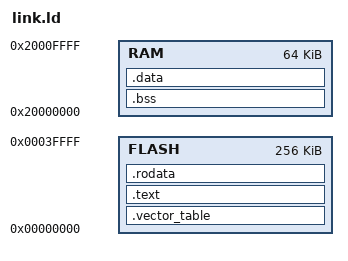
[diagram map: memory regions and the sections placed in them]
/* Memory layout of the LM3S6965 microcontroller */
/* 1K = 1 KiBi = 1024 bytes */
MEMORY
{
  FLASH : ORIGIN = 0x00000000, LENGTH = 256K
  RAM : ORIGIN = 0x20000000, LENGTH = 64K
}

/* The entry point is the reset handler */
ENTRY(Reset);

EXTERN(RESET_VECTOR);
EXTERN(EXCEPTIONS);

/* PROVIDE: 只有左边在所有输入的o中都没找到，才会生效！这样避免使用weak*/
PROVIDE(NMI = DefaultExceptionHandler);
PROVIDE(HardFault = DefaultExceptionHandler);
PROVIDE(MemManage = DefaultExceptionHandler);
PROVIDE(BusFault = DefaultExceptionHandler);
PROVIDE(UsageFault = DefaultExceptionHandler);
PROVIDE(SVCall = DefaultExceptionHandler);
PROVIDE(PendSV = DefaultExceptionHandler);
PROVIDE(SysTick = DefaultExceptionHandler);

SECTIONS
{
  .vector_table ORIGIN(FLASH) :
  {
    /* First entry: initial Stack Pointer value */
    LONG(ORIGIN(RAM) + LENGTH(RAM));

    /* Second entry: reset vector */
    KEEP(*(.vector_table.reset_vector));

    /* The next 14 entries are exception vectors */
    KEEP(*(.vector_table.exceptions));
  } > FLASH

  .text :
  {
    *(.text .text.*);
  } > FLASH

  .rodata :
  {
    *(.rodata .rodata.*);
  } > FLASH

  .bss :
  {
    _sbss = .;
    *(.bss .bss.*);
    _ebss = .;
  } > RAM

  .data :
  {
    _sdata = .;
    *(.data .data.*);
    _edata = .;
  } > RAM

  _sidata = LOADADDR(.data);
  /DISCARD/ :
  {
    *(.ARM.exidx .ARM.exidx.*);
  }
}
